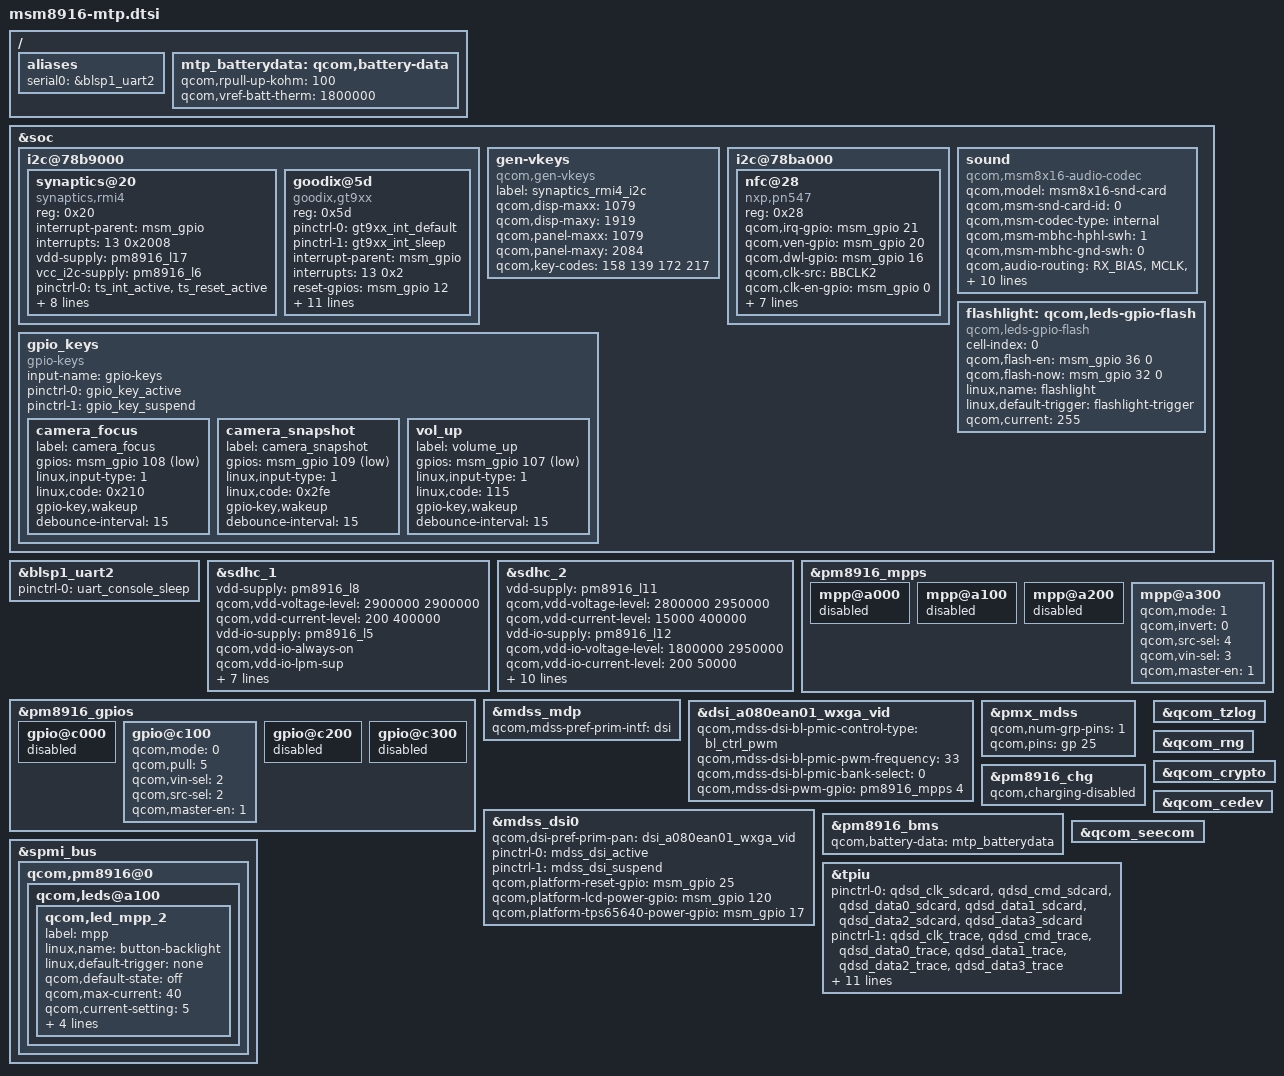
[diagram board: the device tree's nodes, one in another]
/* Copyright (c) 2014, The Linux Foundation. All rights reserved.
 *
 * This program is free software; you can redistribute it and/or modify
 * it under the terms of the GNU General Public License version 2 and
 * only version 2 as published by the Free Software Foundation.
 *
 * This program is distributed in the hope that it will be useful,
 * but WITHOUT ANY WARRANTY; without even the implied warranty of
 * MERCHANTABILITY or FITNESS FOR A PARTICULAR PURPOSE.  See the
 * GNU General Public License for more details.
 */

#include "msm8916.dtsi"
#include "msm8916-pinctrl.dtsi"
#include "msm8916-camera-sensor-mtp.dtsi"

/ {
	aliases {
		serial0 = &blsp1_uart2;
	};
};

&soc {
	i2c@78b9000 { /* BLSP1 QUP5 */
		synaptics@20 {
			compatible = "synaptics,rmi4";
			reg = <0x20>;
			interrupt-parent = <&msm_gpio>;
			interrupts = <13 0x2008>;
			vdd-supply = <&pm8916_l17>;
			vcc_i2c-supply = <&pm8916_l6>;
			/* pins used by touchscreen */
			pinctrl-names = "pmx_ts_active","pmx_ts_suspend";
			pinctrl-0 = <&ts_int_active &ts_reset_active>;
			pinctrl-1 = <&ts_int_suspend &ts_reset_suspend>;
			synaptics,display-coords = <0 0 1079 1919>;
			synaptics,panel-coords = <0 0 1079 2084>;
			synaptics,irq-gpio = <&msm_gpio 13 0x2008>;
			synaptics,reset-gpio = <&msm_gpio 12 0x0>;
			synaptics,i2c-pull-up;
			synaptics,power-down;
			synaptics,disable-gpios;
		};
/*[PLATFORM]-Add-BEGIN by TCTSZ.yaohui.zeng, 2014/04/11, modify TP device tree for pop8LTE */
		goodix@5d {
			compatible = "goodix,gt9xx";
			reg = <0x5d>;
/*[BUGFIX]Add Begin by TCTSZ-LZ 2014-5-5,PR-667466. TP INT pull-up enable.*/
			pinctrl-names = "gt9xx_int_default", "gt9xx_int_suspend";
			pinctrl-0 = <&gt9xx_int_default>;
			pinctrl-1 = <&gt9xx_int_sleep>;
/*[BUGFIX]Add End by TCTSZ-LZ 2014-5-5,PR-667466. TP INT pull-up enable.*/
			interrupt-parent = <&msm_gpio>;
			interrupts = <13 0x2>;
			reset-gpios = <&msm_gpio 12 0x00>;
			interrupt-gpios = <&msm_gpio 13 0x00>;
			vdd-supply = <&pm8916_l17>;
			vcc-i2c-supply = <&pm8916_l6>;
			goodix,panel-coords = <0 0 800 1280>;
			goodix,display-coords = <0 0 800 1280>;
			goodix,button-map= <139 172 158>;
			goodix,product-id = "9271";

			goodix,cfg-data0 = [
				41 20 03 00 05 0A 05 00 01
				08 28 05 55 37 03 05 00 00
				00 02 00 00 00 00 00 00 00
				8F 2F AA 36 34 29 09 00 00
				01 B9 43 1D 00 00 00 00 00
				00 00 00 00 00 02 2B 57 94
				C5 02 07 00 00 04 89 2E 00
				7E 35 00 74 3D 00 6D 46 00
				66 51 00 66 00 00 00 00 00
				00 00 00 00 00 00 00 00 00
				00 00 00 00 00 00 00 00 00
				14 50 00 00 00 00 00 00 00
				00 00 00 00 00 01 04 05 06
				07 08 09 0C 0D 0E 0F 10 11
				14 15 16 17 18 19 00 00 00
				00 00 00 00 00 00 00 0C 0A
				08 07 06 04 02 00 14 13 12
				11 10 0F 0D 19 1B 1C 1E 1F
				20 29 27 21 22 23 24 25 28
				26 FF FF 00 00 00 00 00 00
				00 00 00 00 C0 01];

			goodix,fw_name = "gtp_fw.bin";
			/*goodix,have-touch-key;*/
			goodix,driver-send-cfg;
		};
/*[PLATFORM]-Add-END by TCTSZ.yaohui.zeng, 2014/04/11*/
	};

	gen-vkeys {
		compatible = "qcom,gen-vkeys";
		label = "synaptics_rmi4_i2c";
		qcom,disp-maxx = <1079>;
		qcom,disp-maxy = <1919>;
		qcom,panel-maxx = <1079>;
		qcom,panel-maxy = <2084>;
		qcom,key-codes = <158 139 172 217>;
	};

	i2c@78ba000 { /* BLSP1 QUP6 */
/*[PLATFORM]-Add-BEGIN by TCTSZ.yaohui.zeng, 2014/04/14,add NFC function for pop8lte*/
/*
		nfc-nci@e {
			compatible = "qcom,nfc-nci";
			reg = <0x0e>;
			qcom,irq-gpio = <&msm_gpio 21 0x00>;
			qcom,dis-gpio = <&msm_gpio 20 0x00>;
			qcom,clk-src = "BBCLK2";
			qcom,clk-en-gpio = <&msm_gpio 0 0x00>;
			interrupt-parent = <&msm_gpio>;
			interrupts = <21 0>;
			interrupt-names = "nfc_irq";
			pinctrl-names = "nfc_active","nfc_suspend";
			pinctrl-0 = <&nfc_int_active &nfc_disable_active>;
			pinctrl-1 = <&nfc_int_suspend &nfc_disable_suspend>;
			qcom,clk-gpio = <&pm8916_gpios 2 0>;
			clocks = <&clock_rpm clk_bb_clk2>;
			clock-names = "ref_clk";
		};*/
		nfc@28 {
                        compatible = "nxp,pn547";
                        reg = <0x28>;
                        qcom,irq-gpio = <&msm_gpio 21 0x00>;
                        qcom,ven-gpio = <&msm_gpio 20 0x00>;
                        qcom,dwl-gpio = <&msm_gpio 16 0x00>;
                        qcom,clk-src = "BBCLK2";
                        qcom,clk-en-gpio = <&msm_gpio 0 0x00>;
                        interrupt-parent = <&msm_gpio>;
                        interrupts = <21 0>;
                        qcom,clk-gpio = <&pm8916_gpios 2 0>;
                        pinctrl-names = "nfc_active","nfc_suspend";
                        pinctrl-0 = <&nfc_int_active &nfc_disable_active>;
                        pinctrl-1 = <&nfc_int_suspend &nfc_disable_suspend>;
                        clocks = <&clock_rpm clk_bb_clk2>;
                        clock-names = "ref_clk";
                };
/*[PLATFORM]-Add-END by TCTSZ.yaohui.zeng, 2014/04/14*/
	};

	sound {
		compatible = "qcom,msm8x16-audio-codec";
		qcom,model = "msm8x16-snd-card";
		qcom,msm-snd-card-id = <0>;
		qcom,msm-codec-type = "internal";
/*[PLATFORM]-MOD-BEGIN by TCTSZ.fangyou.wang,2014/04/14,CR-655037 reversal headset detect pin*/
		qcom,msm-mbhc-hphl-swh = <1>;/*<0>;*/
/*[PLATFORM]-MOD-BEGIN by TCTSZ.fangyou.wang,2014/04/14 */
		qcom,msm-mbhc-gnd-swh = <0>;
		qcom,audio-routing =
			"RX_BIAS", "MCLK",
			"SPK_RX_BIAS", "MCLK",
			"INT_LDO_H", "MCLK",
			"MIC BIAS External", "Handset Mic",
			"MIC BIAS Internal2", "Headset Mic",
			"MIC BIAS External", "Secondary Mic",
			"AMIC1", "MIC BIAS External",
			"AMIC2", "MIC BIAS Internal2",
			"AMIC3", "MIC BIAS External";
		pinctrl-names = "cdc_pdm_lines_act",
				"cdc_pdm_lines_sus",
				"cross_conn_det_act",
				"cross_conn_det_sus";
		pinctrl-0 = <&cdc_pdm_lines_act>;
		pinctrl-1 = <&cdc_pdm_lines_sus>;
		pinctrl-2 = <&cross_conn_det_act>;
		pinctrl-3 = <&cross_conn_det_sus>;
	/*	qcom,cdc-us-euro-gpios = <&msm_gpio 120 0>;*/
	};
};

&blsp1_uart2 {
	status = "ok";
	pinctrl-names = "default";
	pinctrl-0 = <&uart_console_sleep>;
};

&soc {
/* [PLATFORM]-Add-BEGIN by TCT.Lu zhi, 2014/05/09, Add flash led function */
	flashlight: qcom,leds-gpio-flash{
		cell-index = <0>;
		compatible = "qcom,leds-gpio-flash";
		status = "okay";
		qcom,flash-en = <&msm_gpio 36 0>;
		qcom,flash-now = <&msm_gpio 32 0>;
		linux,name = "flashlight";
		linux,default-trigger = "flashlight-trigger";
		qcom,current = <255>;
	};
/* [PLATFORM]-Add-END by TCT.Lu zhi, 2014/05/09, Add flash led function */

	gpio_keys {
		compatible = "gpio-keys";
		input-name = "gpio-keys";
		pinctrl-names = "tlmm_gpio_key_active","tlmm_gpio_key_suspend";
		pinctrl-0 = <&gpio_key_active>;
		pinctrl-1 = <&gpio_key_suspend>;

		camera_focus {
			label = "camera_focus";
			gpios = <&msm_gpio 108 0x1>;
			linux,input-type = <1>;
			linux,code = <0x210>;
			gpio-key,wakeup;
			debounce-interval = <15>;
		};

		camera_snapshot {
			label = "camera_snapshot";
			gpios = <&msm_gpio 109 0x1>;
			linux,input-type = <1>;
			linux,code = <0x2fe>;
			gpio-key,wakeup;
			debounce-interval = <15>;
		};

		vol_up {
			label = "volume_up";
			gpios = <&msm_gpio 107 0x1>;
			linux,input-type = <1>;
			linux,code = <115>;
			gpio-key,wakeup;
			debounce-interval = <15>;
		};
	};
};

&sdhc_1 {
	vdd-supply = <&pm8916_l8>;
	qcom,vdd-voltage-level = <2900000 2900000>;
	qcom,vdd-current-level = <200 400000>;

	vdd-io-supply = <&pm8916_l5>;
	qcom,vdd-io-always-on;
	qcom,vdd-io-lpm-sup;
	qcom,vdd-io-voltage-level = <1800000 1800000>;
	qcom,vdd-io-current-level = <200 60000>;

	pinctrl-names = "active", "sleep";
	pinctrl-0 = <&sdc1_clk_on &sdc1_cmd_on &sdc1_data_on>;
	pinctrl-1 = <&sdc1_clk_off &sdc1_cmd_off &sdc1_data_off>;

	qcom,nonremovable;

	status = "ok";
};

&sdhc_2 {
	vdd-supply = <&pm8916_l11>;
	qcom,vdd-voltage-level = <2800000 2950000>;
	qcom,vdd-current-level = <15000 400000>;

	vdd-io-supply = <&pm8916_l12>;
	qcom,vdd-io-voltage-level = <1800000 2950000>;
	qcom,vdd-io-current-level = <200 50000>;

	pinctrl-names = "active", "sleep";
	pinctrl-0 = <&sdc2_clk_on &sdc2_cmd_on &sdc2_data_on &sdc2_cd_on>;
	pinctrl-1 = <&sdc2_clk_off &sdc2_cmd_off &sdc2_data_off &sdc2_cd_off>;

	#address-cells = <0>;
	interrupt-parent = <&sdhc_2>;
	interrupts = <0 1 2>;
	#interrupt-cells = <1>;
	interrupt-map-mask = <0xffffffff>;
	interrupt-map = <0 &intc 0 125 0
			1 &intc 0 221 0
			2 &msm_gpio 38 0>;
	interrupt-names = "hc_irq", "pwr_irq", "status_irq";
	cd-gpios = <&msm_gpio 38 0x1>;

	status = "ok";
};

&pm8916_mpps {
	mpp@a000 { /* MPP 1 */
		/* VDD_PX */
		status = "disabled";
	};

	mpp@a100 { /* MPP 2 */
		/* HR LED */
		status = "disabled";
	};

	mpp@a200 { /* MPP 3 */
		/* VREF DAC */
		status = "disabled";
	};
/*[PLATFORM]-Modify-BEGIN by TCTSZ.yaohui.zeng, 2014/04/16, modify for lcd backlight*/
	mpp@a300 { /* MPP 4 *
		/* Backlight PWM */
		qcom,mode = <1>;		/* Digital output */
		/*qcom,invert = <1>;		/* Output high initially */
		qcom,invert = <0>;        /* INVERT DISABLE */ 
		/*qcom,src-sel = <0>;		/* Constant */
		qcom,src-sel = <4>;		/* DTEST1 */ 
		/*qcom,vin-sel = <0>;		/* VPH_PWR */
		qcom,vin-sel = <3>; 		/* VIN3 */ 
		qcom,master-en = <1>;		/* Enable MPP */
	};
/*[PLATFORM]-Modify-END by TCTSZ.yaohui.zeng, 2014/04/16*/
};

&pm8916_gpios {
	gpio@c000 { /* GPIO 1 */
		/* Battery UICC Alarm */
		status = "disabled";
	};

	gpio@c100 { /* GPIO 2 */
		/* NFC_CLK_REQ */
		qcom,mode = <0>; /* QPNP_PIN_MODE_DIG_IN */
		qcom,pull = <5>; /* QPNP_PIN_PULL_NO */
		qcom,vin-sel = <2>; /* QPNP_PIN_VIN2 */
		qcom,src-sel = <2>; /* QPNP_PIN_SEL_FUNC_1 */
		qcom,master-en = <1>;
	};

	gpio@c200 { /* GPIO 3 */
		/* External regulator control for WTR */
		status = "disabled";
	};

	gpio@c300 { /* GPIO 4 */
		/* External regulator control for APC */
		status = "disabled";
	};
};

#include "dsi-panel-jdi-1080p-video.dtsi"
/*[PLATFORM]-Add-BEGIN by TCTSZ.yaohui.zeng, 2014/04/11, add for pop8LTE LCD*/
#include "dsi-panel-a080ean01-wxga-video.dtsi"
/*[PLATFORM]-Add-END by TCTSZ.yaohui.zeng, 2014/04/11*/

&mdss_mdp {
	qcom,mdss-pref-prim-intf = "dsi";
};
/*[PLATFORM]-Add-BEGIN by TCTSZ.yaohui.zeng, 2014/04/11, modify for pop8LTE LCD*/
&dsi_a080ean01_wxga_vid {
/*[PLATFORM]-Add-END by TCTSZ.yaohui.zeng, 2014/04/11*/
	qcom,mdss-dsi-bl-pmic-control-type = "bl_ctrl_pwm";
/*[PLATFORM]-Modify-BEGIN by TCTSZ.yaohui.zeng, 2014/04/16, modify for lcd backlight PWM frequency*/
	/*qcom,mdss-dsi-bl-pmic-pwm-frequency = <100>;*/
	qcom,mdss-dsi-bl-pmic-pwm-frequency = <33>;
/*[PLATFORM]-Modify-END by TCTSZ.yaohui.zeng, 2014/04/16*/
	qcom,mdss-dsi-bl-pmic-bank-select = <0>;
	qcom,mdss-dsi-pwm-gpio = <&pm8916_mpps 4 0>;

};

&pmx_mdss {
/*[PLATFORM]-Add-BEGIN by TCTSZ.yaohui.zeng, 2014/04/11, modify for pop8LTE LCD*/
/*                 qcom,num-grp-pins = <3>;
	qcom,pins = <&gp 97>, <&gp 25>, <&gp 98>;
 */
                 qcom,num-grp-pins = <1>;
                 qcom,pins = <&gp 25>;
/*[PLATFORM]-Add-END by TCTSZ.yaohui.zeng, 2014/04/11*/
};

&mdss_dsi0 {
       qcom,dsi-pref-prim-pan = <&dsi_a080ean01_wxga_vid>;
	pinctrl-names = "mdss_default", "mdss_sleep";
	pinctrl-0 = <&mdss_dsi_active>;
	pinctrl-1 = <&mdss_dsi_suspend>;
/*[PLATFORM]-Add-BEGIN by TCTSZ.yaohui.zeng, 2014/04/11, modify for pop8LTE LCD*/
/*     qcom,platform-enable-gpio = <&msm_gpio 97 0>;
	qcom,platform-bklight-en-gpio = <&msm_gpio 98 0>;
 */
/*[PLATFORM]-Add-END by TCTSZ.yaohui.zeng, 2014/04/11*/
       qcom,platform-reset-gpio = <&msm_gpio 25 0>;
/*[PLATFORM]-Add-BEGIN by TCTSZ.yaohui.zeng, 2014/04/11, add for pop8LTE LCD*/
	qcom,platform-lcd-power-gpio = <&msm_gpio 120 0>;
	qcom,platform-tps65640-power-gpio = <&msm_gpio 17 0>;
/*[PLATFORM]-Add-END by TCTSZ.yaohui.zeng, 2014/04/11*/
};

&dsi_a080ean01_wxga_vid {
//       qcom,cont-splash-enabled;
};

&pm8916_chg {
	status = "ok";
	qcom,charging-disabled;
};

/ {
	mtp_batterydata: qcom,battery-data {
		qcom,rpull-up-kohm = <100>;
		qcom,vref-batt-therm = <1800000>;

		#include "batterydata-palladium.dtsi"
	};
};

&pm8916_bms {
	status = "ok";
	qcom,battery-data = <&mtp_batterydata>;
};

&spmi_bus {
	qcom,pm8916@0 {
		qcom,leds@a100 {
			status = "okay";
			qcom,led_mpp_2 {
				label = "mpp";
				linux,name = "button-backlight";
				linux,default-trigger = "none";
				qcom,default-state = "off";
				qcom,max-current = <40>;
				qcom,current-setting = <5>;
				qcom,id = <6>;
				qcom,mode = "manual";
				qcom,source-sel = <1>;
				qcom,mode-ctrl = <0x60>;
			};
		};
	};
};

&qcom_tzlog {
	status = "okay";
};

&qcom_rng {
	status = "okay";
};

&qcom_crypto {
	status = "okay";
};

&qcom_cedev {
	status = "okay";
};

&qcom_seecom {
	status = "okay";
};

/* CoreSight */
&tpiu {
      pinctrl-names = "sdcard", "trace", "swduart",
		      "swdtrc", "jtag", "spmi";
       /* NIDnT */
      pinctrl-0 = <&qdsd_clk_sdcard &qdsd_cmd_sdcard
                  &qdsd_data0_sdcard &qdsd_data1_sdcard
                  &qdsd_data2_sdcard &qdsd_data3_sdcard>;
      pinctrl-1 = <&qdsd_clk_trace &qdsd_cmd_trace
                  &qdsd_data0_trace &qdsd_data1_trace
                  &qdsd_data2_trace &qdsd_data3_trace>;
      pinctrl-2 = <&qdsd_cmd_swduart &qdsd_data0_swduart
                  &qdsd_data1_swduart &qdsd_data2_swduart
                  &qdsd_data3_swduart>;
      pinctrl-4 = <&qdsd_clk_swdtrc &qdsd_cmd_swdtrc
                  &qdsd_data0_swdtrc &qdsd_data1_swdtrc
                  &qdsd_data2_swdtrc &qdsd_data3_swdtrc>;
      pinctrl-5 = <&qdsd_cmd_jtag &qdsd_data0_jtag
                  &qdsd_data1_jtag &qdsd_data2_jtag
                  &qdsd_data3_jtag>;
      pinctrl-6 = <&qdsd_clk_spmi &qdsd_cmd_spmi
                  &qdsd_data0_spmi &qdsd_data3_spmi>;
};
